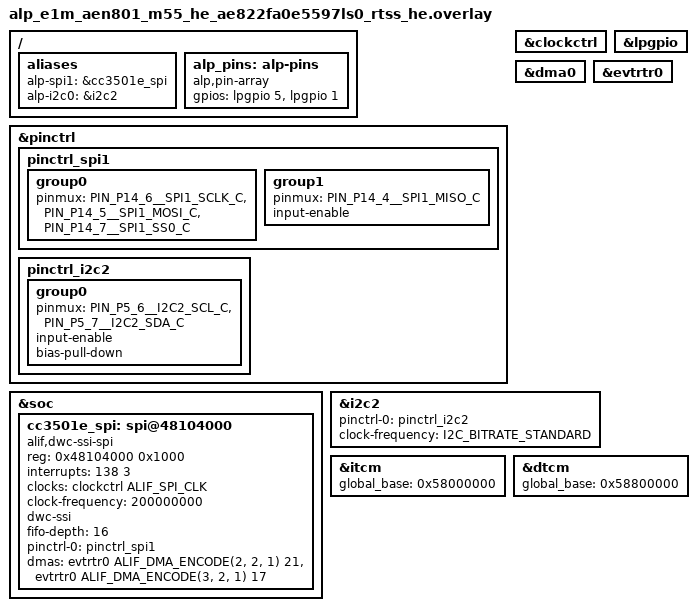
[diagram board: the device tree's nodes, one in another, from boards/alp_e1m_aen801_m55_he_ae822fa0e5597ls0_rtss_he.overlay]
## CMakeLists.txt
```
# SPDX-License-Identifier: Apache-2.0

cmake_minimum_required(VERSION 3.20)

find_package(Zephyr REQUIRED HINTS $ENV{ZEPHYR_BASE})
project(aen_cc3501e_companion_tour LANGUAGES C)

target_sources(app PRIVATE src/main.c)
# Reusable SoM bring-up helper (cc3501e_bridge_bringup): the one-call CC3501E
# bridge init the example + applications use. Copyable template -- see
# cc3501e_bridge.h. (Same helper as aen-cc3501e-bringup; examples are meant to
# be self-contained, copyable starting points.)
target_sources(app PRIVATE src/cc3501e_bridge.c)
# E1M-AEN GPIO-proxy route table: strong override of the WEAK
# cc3501e_gpio_routes[] in src/backends/gpio/cc3501e_proxy_routes_weak.c
# (E1M IO pin_id -> raw CC3501E GPIO). Auto-generated by
# scripts/gen_cc3501e_gpio_routes.py -- do not edit by hand, regenerate.
# Built unconditionally; only consulted when CONFIG_ALP_SDK_GPIO_CC3501E_PROXY is on.
target_sources(app PRIVATE src/cc3501e_gpio_routes.c)
```

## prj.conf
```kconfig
# SPDX-License-Identifier: Apache-2.0
#
# CONFIG_SPI / CONFIG_GPIO are pulled in from board.yaml's `peripherals:`
# block (via the generated alp.conf); this file carries only the console.
CONFIG_PRINTK=y
CONFIG_LOG=y

# The tour uses busy/sleep waits + a few driver scratch buffers + a socket
# receive buffer; a generous main-thread stack keeps them comfortable.
CONFIG_MAIN_STACK_SIZE=4096

# Link the app at the HE MRAM app partition (0x80010000) so its vector table
# matches the ATOC load address (app-zephyr-he.json mramAddress=0x80010000).
# FLASH_BASE is the full MRAM (0x80000000); without this 0x10000 offset the
# image links at 0x80000000 and the SES boots it 64 KB low -> fault/no-boot.
CONFIG_FLASH_LOAD_OFFSET=0x10000

# Route the proxied E1M IOs (cc3501e_gpio_routes[] in src/cc3501e_gpio_routes.c)
# through the CC3501E bridge: alp_gpio_open(ALP_E1M_GPIO_IOxx) for a mapped IO
# goes over the inter-chip link; the Alif's own pins delegate to the platform
# GPIO driver.  The final tour step reads a proxied IO through this path.
CONFIG_ALP_SDK_GPIO_CC3501E_PROXY=y
```

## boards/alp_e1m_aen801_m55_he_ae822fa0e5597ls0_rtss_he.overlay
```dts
/*
 * Copyright (c) 2026 Alp Lab AB
 * SPDX-License-Identifier: Apache-2.0
 *
 * Inter-chip wiring for the CC3501E bring-up on the E1M-AEN801 (Alif
 * Ensemble E8, M55-HE).  Declares the SoM-internal Alif<->CC3501E link:
 * the SPI1 master bus + the two host-driven control nets, all from
 * metadata/e1m_modules/aen/inter-chip.tsv:
 *
 *   SPI1.SCK  P14_6   SPI1.MOSI P14_5   SPI1.MISO P14_4   (-> CC3501E GPIO_27/28/29)
 *   WIFI_EN   P15_5 (lpgpio 5)          E_WIFI.NRST P15_1_FLEX (lpgpio 1)
 *
 * "P15" is the Alif low-power GPIO island (lpgpio @ 0x42002000); the
 * _FLEX pads are its pins.  P14 is a main-domain port used here purely as
 * the SPI1 function via pinctrl, so no gpio14 controller node is needed.
 *
 * BENCH-UNVERIFIED.  Like the rest of the alp-sdk Alif peripheral layer
 * (zephyr/dts/alif/ensemble_e8_peripherals.dtsi), the addresses/IRQs are
 * transcribed from the Apache-2.0 alifsemi/zephyr_alif fork + the AE822
 * TRM and have NOT been validated on silicon.  The SPI1 pinctrl macros are
 * RESOLVED against zephyr/dt-bindings/pinctrl/alif-ensemble-pinctrl.h
 * (SPI1 on P14_4/5/6 = alt-2, the `_C` suffix) and the LP-GPIO mux is the
 * reset default (alt-0 = LPGPIO); the one remaining genuine unknown is the
 * SPI1 IRQ number (upstream Zephyr declares no SPI node, so it is not in
 * the build tree) -- confirm it against the AE822 TRM before relying on
 * the interrupt-driven path on silicon.
 *
 * Also enables i2c2 (P5_6 SCL_C / P5_7 SDA_C) + the `alp-i2c0` alias -- the
 * on-module EEPROM manifest bus alp_hw_info_read() opens as bus_id 0.
 * Without it the manifest read structurally cannot succeed and the banner
 * falls back to the raw board target instead of the SoM identity; see #1870.
 * Same pinctrl (input-enable + bias-pull-down) as
 * examples/peripheral-io/alp-console's bench-validated overlay -- do NOT
 * "correct" the pull direction.
 */

#include <zephyr/dt-bindings/pinctrl/alif-ensemble-pinctrl.h>
#include <zephyr/dt-bindings/gpio/gpio.h>
#include <zephyr/dt-bindings/dma/alif_dma_event_router.h>
#include <zephyr/dt-bindings/i2c/i2c.h>

&pinctrl {
	/*
	 * SPI1 master on P14_6 (SCK) / P14_5 (MOSI) / P14_4 (MISO).
	 *
	 * RESOLVED against alif-ensemble-pinctrl.h: the SPI1 functions on these
	 * three pads are alt-2, named with the `_C` suffix
	 * (PIN_P14_6__SPI1_SCLK_C = ALIF_PINMUX(14, 6, 2), etc.).  input-enable
	 * on MISO so the pad can sense the slave's drive (the same read-enable
	 * requirement the I2C pads need on this SoC).
	 */
	pinctrl_spi1: pinctrl_spi1 {
		group0 {
			/* Hardware SS0 chip-select (P14_7 = SPI1_SS0_C) -- dwc-ssi master
			 * drives SS0 per transfer to frame the CC3501E slave. */
			pinmux = <PIN_P14_6__SPI1_SCLK_C>, <PIN_P14_5__SPI1_MOSI_C>,
				 <PIN_P14_7__SPI1_SS0_C>;
		};
		group1 {
			pinmux = <PIN_P14_4__SPI1_MISO_C>;
			input-enable;
		};
	};

	/* I2C2 master (EEPROM manifest bus): SCL P5_6 / SDA P5_7 (_C).  Same
	 * pad config as alp-console's bench-validated overlay -- input-enable
	 * for ACK-detect, bias-pull-down (the pad DSC value Alif's reference
	 * uses; the bus is pulled up on the carrier via R95/R96). */
	pinctrl_i2c2: pinctrl_i2c2 {
		group0 {
			pinmux = <PIN_P5_6__I2C2_SCL_C>, <PIN_P5_7__I2C2_SDA_C>;
			input-enable;
			bias-pull-down;
		};
	};
};

/*
 * DWC_ssi SPI1 (AHB) -- the on-SoM CC3501E inter-chip link.  Deliberately
 * NOT in ensemble_e8_peripherals.dtsi (that dtsi declares only the
 * customer-facing edge SPI0); this is the SoM-internal Wi-Fi link, so it
 * lives in the consuming app's overlay.  Same driver + flags as spi0
 * (compatible "alif,dwc-ssi-spi", dwc-ssi layout, fifo-depth 16,
 * frequency-only ALIF_SPI_CLK).
 *
 * reg 0x48104000 = SPI1 base (spi0 is 0x48103000, +0x1000/instance).
 * BENCH-TBD: interrupts = <138 3> follows the consecutive pattern from
 * spi0's IRQ 137 -- confirm SPI1_IRQ against the fork's e1.dtsi / TRM.
 *
 * No cs-gpios: P14_7 is muxed as SPI1_SS0_C above and the dwc-ssi peripheral
 * drives hardware SS0 per transfer.  The host opens ALP_SPI_NO_CS so no GPIO CS
 * is installed, allowing the SPI driver to use its hardware slave-select path.
 */
&clockctrl {
	status = "okay";
};

&soc {
	cc3501e_spi: spi@48104000 {
		compatible = "alif,dwc-ssi-spi";
		#address-cells = <1>;
		#size-cells = <0>;
		reg = <0x48104000 0x1000>;
		interrupts = <138 3>;          /* BENCH-TBD: confirm SPI1 IRQ */
		clocks = <&clockctrl ALIF_SPI_CLK>;
		/*
		 * ROOT-CAUSE FIX 2026-06-16: spi_dw_alif's configure takes the
		 * clock-control path when no clock-frequency is set, and that path
		 * fails (-EINVAL) for the gateless dummy ALIF_SPI_CLK -> every
		 * transceive returned ALP_ERR_INVAL with zero SCLK (witness fail_step=1,
		 * zerr=-EINVAL). Providing the SSI input clock here makes the driver
		 * use it directly and skip the failing clock-control path. The SSI
		 * functional clock is 200 MHz (E8 HWRM); BAUDR = clk/freq_hz.
		 */
		clock-frequency = <200000000>; /* real SSI functional clock (was mis-set 400M; proven via BAUDR scaling) */
		dwc-ssi;
		fifo-depth = <16>;
		pinctrl-0 = <&pinctrl_spi1>;
		pinctrl-names = "default";
		status = "okay";
	};
};

/*
 * Enable the LP GPIO island so WIFI_EN (P15_5) and E_WIFI.NRST
 * (P15_1_FLEX) are drivable as outputs.  gpio_dw needs no clocks/pinctrl
 * on the controller, and the pad->GPIO mux needs no pinctrl group either:
 * RESOLVED against alif-ensemble-pinctrl.h -- P15_1/P15_5 function 0 (the
 * reset default) IS LPGPIO (PIN_P15_x__LPGPIO = ALIF_PINMUX(15, x, 0)).
 */
&lpgpio {
	status = "okay";
};

/* P2_6 (E1M AH7 / I2S1_SCLK) is NOT the CC3501E READY net on the R2 module this
 * bridge targets -- it is E1M pad AH7 / I2S1_SCLK, which the E1M EVK carrier
 * repurposes as the Arduino header's CK_RST (metadata/boards/e1m-evk.yaml);
 * the real READY net lands on E1M pad G3 / IO16 instead
 * (metadata/e1m_modules/aen/from-cc3501e.tsv). This app therefore does not
 * enable &gpio2 or claim P2_6 as READY -- see src/cc3501e_bridge.c and
 * chips/cc3501e/cc3501e_core.c's cc3501e_reply_gate() comment. A board (or a
 * hand-reworked r1 unit) that genuinely wires GPIO17 to P2_6 can opt back
 * in: enable &gpio2, add a pinctrl group that enables P2_6's INPUT BUFFER --
 * reset-default mux already IS GPIO, but GPIO function alone does not enable
 * the input path; skip that group and cc3501e_reply_gate()'s read comes back
 * a constant 0 forever, indistinguishable from a stuck-LOW pad -- add an
 * alp_pins entry for it, and set fw->ready_pin in cc3501e_bridge_bringup(). */

/*
 * Host-side peripheral DMA for continuous SPI streams over the CC3501E bridge.
 * SPI1 is a MAIN-domain peripheral, so per the AE822 DFP soc_dma_map (SPI1_DMA=0,
 * group 2, TX req 21 / RX req 17) it routes through the SYSTOP DMA0 via its event
 * router evtrtr0 (4 groups -> group 2 valid) -- NOT the M55-HE-local DMA2/evtrtr2
 * (1 group, for LP peripherals; wiring SPI1 there leaves the channel Waiting-For-
 * Peripheral forever -- SPI1's request line isn't on the HE router).  DMA0's clock
 * is SYSTOP (already on -- the app drives SPI1/GPIO in the same region); its
 * PL330 boot-manager security latch (CLKCTRL_PER_MST) is in dma_alif_boot_latch.c.
 * The fork PL330 driver statically allocates the per-channel ucode + remaps it via
 * local_to_global(), so no external `microcode` prop is needed.
 *
 * dma0 + evtrtr0 are now declared in ensemble_e8_peripherals.dtsi (disabled
 * by default, alp-sdk issue #1815); this overlay only enables them.
 */
&dma0 {
	status = "okay";
};

&evtrtr0 {
	status = "okay";
};

/*
 * Route the bridge SPI1 through evtrtr0 to DMA0.  Cell encoding
 * (ALIF_DMA_ENCODE(channel, dma_group, handshake), periph_req):
 *   TX = PL330 ch2, evtrtr group 2, handshake on, SPI1 TX periph req 21
 *   RX = PL330 ch3, evtrtr group 2, handshake on, SPI1 RX periph req 17
 * (AE822 DFP soc_dma_map.h: SPI1 group 2, TX 21 / RX 17.)
 */
&cc3501e_spi {
	dmas = <&evtrtr0 ALIF_DMA_ENCODE(2, 2, 1) 21>,
	       <&evtrtr0 ALIF_DMA_ENCODE(3, 2, 1) 17>;
	dma-names = "txdma", "rxdma";
};

&i2c2 {
	status = "okay";
	pinctrl-0 = <&pinctrl_i2c2>;
	pinctrl-names = "default";
	clock-frequency = <I2C_BITRATE_STANDARD>;   /* 100 kHz */
};

/ {
	aliases {
		/* bus_id 1 in alp_spi_open() -> this controller. */
		alp-spi1 = &cc3501e_spi;
		alp-i2c0 = &i2c2;   /* bus 0 for alp_hw_info_read() -> EEPROM manifest */
	};

	/*
	 * Compact 2-entry control array for the SoM-internal CC3501E control
	 * nets, in the order the app's CC3501E_PIN_* indices expect.  These are
	 * NOT E1M edge pads, so this bring-up app intentionally does NOT use the
	 * 52-slot positional E1M map; a production board file appends such
	 * SoM-internal control nets after the E1M pad slots.  No READY entry
	 * here -- see the P2_6 comment above &gpio2's removal further up.
	 */
	alp_pins: alp-pins {
		compatible = "alp,pin-array";
		gpios = <&lpgpio 5 GPIO_ACTIVE_HIGH>, /* [0] WIFI_EN     (P15_5)      */
			<&lpgpio 1 GPIO_ACTIVE_HIGH>; /* [1] E_WIFI.NRST (P15_1_FLEX) */
	};
};

/*
 * Global-bus aliases of the M55-HE TCMs, needed by hal_alif soc_memory_map.h
 * local_to_global() -- the PL330 (AXI master) reaches TCM-resident buffers only
 * via these global windows.  Values from the AE822 M55-HE map (sdk-alif fork
 * ensemble_rtss_he.dtsi): ITCM 0x0->0x58000000, DTCM 0x20000000->0x58800000.
 * (DMA stream buffers still belong in SRAM0 0x02000000, which is already global
 * -> local_to_global() returns it unchanged.)
 */
&itcm {
	global_base = <0x58000000>;
};
&dtcm {
	global_base = <0x58800000>;
};
```

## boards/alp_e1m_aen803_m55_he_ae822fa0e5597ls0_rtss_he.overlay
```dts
/*
 * Copyright (c) 2026 Alp Lab AB
 * SPDX-License-Identifier: Apache-2.0
 *
 * Inter-chip wiring for the CC3501E bring-up on the E1M-AEN803 (Alif
 * Ensemble E8, M55-HE).  Declares the SoM-internal Alif<->CC3501E link:
 * the SPI1 master bus + the two host-driven control nets, all from
 * metadata/e1m_modules/aen/inter-chip.tsv:
 *
 *   SPI1.SCK  P14_6   SPI1.MOSI P14_5   SPI1.MISO P14_4   (-> CC3501E GPIO_27/28/29)
 *   WIFI_EN   P15_5 (lpgpio 5)          E_WIFI.NRST P15_1_FLEX (lpgpio 1)
 *
 * "P15" is the Alif low-power GPIO island (lpgpio @ 0x42002000); the
 * _FLEX pads are its pins.  P14 is a main-domain port used here purely as
 * the SPI1 function via pinctrl, so no gpio14 controller node is needed.
 *
 * BENCH-UNVERIFIED.  Like the rest of the alp-sdk Alif peripheral layer
 * (zephyr/dts/alif/ensemble_e8_peripherals.dtsi), the addresses/IRQs are
 * transcribed from the Apache-2.0 alifsemi/zephyr_alif fork + the AE822
 * TRM and have NOT been validated on silicon.  The SPI1 pinctrl macros are
 * RESOLVED against zephyr/dt-bindings/pinctrl/alif-ensemble-pinctrl.h
 * (SPI1 on P14_4/5/6 = alt-2, the `_C` suffix) and the LP-GPIO mux is the
 * reset default (alt-0 = LPGPIO); the one remaining genuine unknown is the
 * SPI1 IRQ number (upstream Zephyr declares no SPI node, so it is not in
 * the build tree) -- confirm it against the AE822 TRM before relying on
 * the interrupt-driven path on silicon.
 *
 * Also enables i2c2 (P5_6 SCL_C / P5_7 SDA_C) + the `alp-i2c0` alias -- the
 * on-module EEPROM manifest bus alp_hw_info_read() opens as bus_id 0.
 * Without it the manifest read structurally cannot succeed and the banner
 * falls back to the raw board target instead of the SoM identity; see #1870.
 * Same pinctrl (input-enable + bias-pull-down) as
 * examples/peripheral-io/alp-console's bench-validated overlay -- do NOT
 * "correct" the pull direction.
 */

#include <zephyr/dt-bindings/pinctrl/alif-ensemble-pinctrl.h>
#include <zephyr/dt-bindings/gpio/gpio.h>
#include <zephyr/dt-bindings/dma/alif_dma_event_router.h>
#include <zephyr/dt-bindings/i2c/i2c.h>

&pinctrl {
	/*
	 * SPI1 master on P14_6 (SCK) / P14_5 (MOSI) / P14_4 (MISO).
	 *
	 * RESOLVED against alif-ensemble-pinctrl.h: the SPI1 functions on these
	 * three pads are alt-2, named with the `_C` suffix
	 * (PIN_P14_6__SPI1_SCLK_C = ALIF_PINMUX(14, 6, 2), etc.).  input-enable
	 * on MISO so the pad can sense the slave's drive (the same read-enable
	 * requirement the I2C pads need on this SoC).
	 */
	pinctrl_spi1: pinctrl_spi1 {
		group0 {
			/* Hardware SS0 chip-select (P14_7 = SPI1_SS0_C) -- dwc-ssi master
			 * drives SS0 per transfer to frame the CC3501E slave. */
			pinmux = <PIN_P14_6__SPI1_SCLK_C>, <PIN_P14_5__SPI1_MOSI_C>,
				 <PIN_P14_7__SPI1_SS0_C>;
		};
		group1 {
			pinmux = <PIN_P14_4__SPI1_MISO_C>;
			input-enable;
		};
	};

	/* I2C2 master (EEPROM manifest bus): SCL P5_6 / SDA P5_7 (_C).  Same
	 * pad config as alp-console's bench-validated overlay -- input-enable
	 * for ACK-detect, bias-pull-down (the pad DSC value Alif's reference
	 * uses; the bus is pulled up on the carrier via R95/R96). */
	pinctrl_i2c2: pinctrl_i2c2 {
		group0 {
			pinmux = <PIN_P5_6__I2C2_SCL_C>, <PIN_P5_7__I2C2_SDA_C>;
			input-enable;
			bias-pull-down;
		};
	};
};

/*
 * DWC_ssi SPI1 (AHB) -- the on-SoM CC3501E inter-chip link.  Deliberately
 * NOT in ensemble_e8_peripherals.dtsi (that dtsi declares only the
 * customer-facing edge SPI0); this is the SoM-internal Wi-Fi link, so it
 * lives in the consuming app's overlay.  Same driver + flags as spi0
 * (compatible "alif,dwc-ssi-spi", dwc-ssi layout, fifo-depth 16,
 * frequency-only ALIF_SPI_CLK).
 *
 * reg 0x48104000 = SPI1 base (spi0 is 0x48103000, +0x1000/instance).
 * BENCH-TBD: interrupts = <138 3> follows the consecutive pattern from
 * spi0's IRQ 137 -- confirm SPI1_IRQ against the fork's e1.dtsi / TRM.
 *
 * No cs-gpios: P14_7 is muxed as SPI1_SS0_C above and the dwc-ssi peripheral
 * drives hardware SS0 per transfer.  The host opens ALP_SPI_NO_CS so no GPIO CS
 * is installed, allowing the SPI driver to use its hardware slave-select path.
 */
&clockctrl {
	status = "okay";
};

&soc {
	cc3501e_spi: spi@48104000 {
		compatible = "alif,dwc-ssi-spi";
		#address-cells = <1>;
		#size-cells = <0>;
		reg = <0x48104000 0x1000>;
		interrupts = <138 3>;          /* BENCH-TBD: confirm SPI1 IRQ */
		clocks = <&clockctrl ALIF_SPI_CLK>;
		/*
		 * ROOT-CAUSE FIX 2026-06-16: spi_dw_alif's configure takes the
		 * clock-control path when no clock-frequency is set, and that path
		 * fails (-EINVAL) for the gateless dummy ALIF_SPI_CLK -> every
		 * transceive returned ALP_ERR_INVAL with zero SCLK (witness fail_step=1,
		 * zerr=-EINVAL). Providing the SSI input clock here makes the driver
		 * use it directly and skip the failing clock-control path. The SSI
		 * functional clock is 200 MHz (E8 HWRM); BAUDR = clk/freq_hz.
		 */
		clock-frequency = <200000000>; /* real SSI functional clock (was mis-set 400M; proven via BAUDR scaling) */
		dwc-ssi;
		fifo-depth = <16>;
		pinctrl-0 = <&pinctrl_spi1>;
		pinctrl-names = "default";
		status = "okay";
	};
};

/*
 * Enable the LP GPIO island so WIFI_EN (P15_5) and E_WIFI.NRST
 * (P15_1_FLEX) are drivable as outputs.  gpio_dw needs no clocks/pinctrl
 * on the controller, and the pad->GPIO mux needs no pinctrl group either:
 * RESOLVED against alif-ensemble-pinctrl.h -- P15_1/P15_5 function 0 (the
 * reset default) IS LPGPIO (PIN_P15_x__LPGPIO = ALIF_PINMUX(15, x, 0)).
 */
&lpgpio {
	status = "okay";
};

/* P2_6 (E1M AH7 / I2S1_SCLK) is NOT the CC3501E READY net on the R2 module this
 * bridge targets -- it is E1M pad AH7 / I2S1_SCLK, which the E1M EVK carrier
 * repurposes as the Arduino header's CK_RST (metadata/boards/e1m-evk.yaml);
 * the real READY net lands on E1M pad G3 / IO16 instead
 * (metadata/e1m_modules/aen/from-cc3501e.tsv). This app therefore does not
 * enable &gpio2 or claim P2_6 as READY -- see src/cc3501e_bridge.c and
 * chips/cc3501e/cc3501e_core.c's cc3501e_reply_gate() comment. A board (or a
 * hand-reworked r1 unit) that genuinely wires GPIO17 to P2_6 can opt back
 * in: enable &gpio2, add a pinctrl group that enables P2_6's INPUT BUFFER --
 * reset-default mux already IS GPIO, but GPIO function alone does not enable
 * the input path; skip that group and cc3501e_reply_gate()'s read comes back
 * a constant 0 forever, indistinguishable from a stuck-LOW pad -- add an
 * alp_pins entry for it, and set fw->ready_pin in cc3501e_bridge_bringup(). */

/*
 * Host-side peripheral DMA for continuous SPI streams over the CC3501E bridge.
 * SPI1 is a MAIN-domain peripheral, so per the AE822 DFP soc_dma_map (SPI1_DMA=0,
 * group 2, TX req 21 / RX req 17) it routes through the SYSTOP DMA0 via its event
 * router evtrtr0 (4 groups -> group 2 valid) -- NOT the M55-HE-local DMA2/evtrtr2
 * (1 group, for LP peripherals; wiring SPI1 there leaves the channel Waiting-For-
 * Peripheral forever -- SPI1's request line isn't on the HE router).  DMA0's clock
 * is SYSTOP (already on -- the app drives SPI1/GPIO in the same region); its
 * PL330 boot-manager security latch (CLKCTRL_PER_MST) is in dma_alif_boot_latch.c.
 * The fork PL330 driver statically allocates the per-channel ucode + remaps it via
 * local_to_global(), so no external `microcode` prop is needed.
 *
 * dma0 + evtrtr0 are now declared in ensemble_e8_peripherals.dtsi (disabled
 * by default, alp-sdk issue #1815); this overlay only enables them.
 */
&dma0 {
	status = "okay";
};

&evtrtr0 {
	status = "okay";
};

/*
 * Route the bridge SPI1 through evtrtr0 to DMA0.  Cell encoding
 * (ALIF_DMA_ENCODE(channel, dma_group, handshake), periph_req):
 *   TX = PL330 ch2, evtrtr group 2, handshake on, SPI1 TX periph req 21
 *   RX = PL330 ch3, evtrtr group 2, handshake on, SPI1 RX periph req 17
 * (AE822 DFP soc_dma_map.h: SPI1 group 2, TX 21 / RX 17.)
 */
&cc3501e_spi {
	dmas = <&evtrtr0 ALIF_DMA_ENCODE(2, 2, 1) 21>,
	       <&evtrtr0 ALIF_DMA_ENCODE(3, 2, 1) 17>;
	dma-names = "txdma", "rxdma";
};

&i2c2 {
	status = "okay";
	pinctrl-0 = <&pinctrl_i2c2>;
	pinctrl-names = "default";
	clock-frequency = <I2C_BITRATE_STANDARD>;   /* 100 kHz */
};

/ {
	aliases {
		/* bus_id 1 in alp_spi_open() -> this controller. */
		alp-spi1 = &cc3501e_spi;
		alp-i2c0 = &i2c2;   /* bus 0 for alp_hw_info_read() -> EEPROM manifest */
	};

	/*
	 * Compact 2-entry control array for the SoM-internal CC3501E control
	 * nets, in the order the app's CC3501E_PIN_* indices expect.  These are
	 * NOT E1M edge pads, so this bring-up app intentionally does NOT use the
	 * 52-slot positional E1M map; a production board file appends such
	 * SoM-internal control nets after the E1M pad slots.  No READY entry
	 * here -- see the P2_6 comment above &gpio2's removal further up.
	 */
	alp_pins: alp-pins {
		compatible = "alp,pin-array";
		gpios = <&lpgpio 5 GPIO_ACTIVE_HIGH>, /* [0] WIFI_EN     (P15_5)      */
			<&lpgpio 1 GPIO_ACTIVE_HIGH>; /* [1] E_WIFI.NRST (P15_1_FLEX) */
	};
};

/*
 * Global-bus aliases of the M55-HE TCMs, needed by hal_alif soc_memory_map.h
 * local_to_global() -- the PL330 (AXI master) reaches TCM-resident buffers only
 * via these global windows.  Values from the AE822 M55-HE map (sdk-alif fork
 * ensemble_rtss_he.dtsi): ITCM 0x0->0x58000000, DTCM 0x20000000->0x58800000.
 * (DMA stream buffers still belong in SRAM0 0x02000000, which is already global
 * -> local_to_global() returns it unchanged.)
 */
&itcm {
	global_base = <0x58000000>;
};
&dtcm {
	global_base = <0x58800000>;
};
```

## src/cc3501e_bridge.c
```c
/*
 * SPDX-License-Identifier: Apache-2.0
 * Copyright 2026 Alp Lab AB
 *
 * E1M-AEN SoM CC3501E bridge bring-up helper -- see cc3501e_bridge.h.
 */

#include "cc3501e_bridge.h"

#if defined(CONFIG_BOARD_ALP_E1M_AEN801_M55_HE)
#include <zephyr/arch/cpu.h>
#include <zephyr/sys/sys_io.h>
/*
 * AEN LP-pad mux (Alif Ensemble E8, M55-HE).  WIFI_EN (P15_5) and nRESET (P15_1)
 * are on the Alif LP-GPIO island, bound by the generic snps,designware-gpio driver
 * which does NOT apply Alif pinctrl -- so the LP pads stay un-muxed and their output
 * drivers OFF (confirmed on silicon: WIFI_EN never powers the CC3501E until these
 * regs are set).  0x23 = the Alif GPIO-output pad config (driver + read-enable +
 * drive strength).  TODO: drop this raw poke once the Alif GPIO backend muxes the LP
 * island via pinctrl.
 */
#define ALIF_LPGPIO_PADCTRL_BASE 0x42007000u
#define ALIF_PAD_GPIO_OUTPUT     0x23u
static void aen_lp_pads_enable_output(void)
{
	sys_write32(ALIF_PAD_GPIO_OUTPUT, ALIF_LPGPIO_PADCTRL_BASE + 5u * 4u); /* P15_5 WIFI_EN */
	sys_write32(ALIF_PAD_GPIO_OUTPUT, ALIF_LPGPIO_PADCTRL_BASE + 1u * 4u); /* P15_1 nRESET  */
}
#else
static inline void aen_lp_pads_enable_output(void)
{
}
#endif

alp_status_t cc3501e_bridge_bringup(cc3501e_t *fw)
{
	if (fw == NULL) {
		return ALP_ERR_INVAL;
	}

	/* 1. Control pins: WIFI_EN (supply gate) + nRESET.  These are Alif LP-GPIO
	 *    pads, not E1M edge pads -- the SoM owns them. */
	alp_gpio_t *wifi_en = alp_gpio_open(CC3501E_BRIDGE_PIN_WIFI_EN);
	alp_gpio_t *nrst    = alp_gpio_open(CC3501E_BRIDGE_PIN_NRST);
	if (wifi_en == NULL || nrst == NULL) {
		if (wifi_en != NULL) {
			alp_gpio_close(wifi_en);
		}
		if (nrst != NULL) {
			alp_gpio_close(nrst);
		}
		return ALP_ERR_NOT_PRESENT_ON_THIS_SOC;
	}
	aen_lp_pads_enable_output();
	(void)alp_gpio_configure(wifi_en, ALP_GPIO_OUTPUT, ALP_GPIO_PULL_NONE);
	(void)alp_gpio_configure(nrst, ALP_GPIO_OUTPUT, ALP_GPIO_PULL_NONE);

	/* 2. Inter-chip SPI (Alif = master).  No chip-select this HW rev -- the link is
	 *    fixed-count lockstep (ALP_SPI_NO_CS); mode 0 matches the CC3501E vendor
	 *    image frameFormat. */
	alp_spi_t *spi = alp_spi_open(&(alp_spi_config_t){
	    .bus_id        = CC3501E_BRIDGE_SPI_BUS_ID,
	    .freq_hz       = CC3501E_BRIDGE_SPI_FREQ_HZ,
	    .mode          = ALP_SPI_MODE_0,
	    .bits_per_word = 8u,
	    .cs_pin_id     = ALP_SPI_NO_CS,
	});
	if (spi == NULL) {
		alp_gpio_close(wifi_en);
		alp_gpio_close(nrst);
		return ALP_ERR_NOT_PRESENT_ON_THIS_SOC;
	}

#if CC3501E_BRIDGE_RX_SAMPLE_DLY > 0
	/* Raise the SCLK past 1 MHz: the DW SSI RX_SAMPLE_DLY register (0xf0) delays
	 * the MISO capture point by N ssi_clk cycles to cover the on-SoM trace + crossed
	 * data round-trip.  Zephyr spi_dw never writes it (leaves 0), so without this
	 * >1 MHz mis-samples MISO (cold reqhdr_rx=0xFFFFFFFF).  Written with SSI disabled
	 * (SSIENR=0); persists across the driver's per-transfer configure.  Value is
	 * silicon-tuned -- sweep CC3501E_BRIDGE_RX_SAMPLE_DLY at the target SCLK. */
	{
		volatile uint32_t *ssienr =
		    (volatile uint32_t *)(uintptr_t)(CC3501E_BRIDGE_SPI1_BASE + 0x08u);
		volatile uint32_t *rsd = (volatile uint32_t *)(uintptr_t)(CC3501E_BRIDGE_SPI1_BASE + 0xf0u);
		uint32_t           en  = *ssienr;
		*ssienr                = 0u;
		*rsd                   = (uint32_t)CC3501E_BRIDGE_RX_SAMPLE_DLY;
		*ssienr                = en;
	}
#endif

	/* 3. Bind the bus + control pins; attach the GPIO proxy (proxied E1M IOs then
	 *    route over the bridge); run the power + reset sequence (TI SWRU626 + the
	 *    Puya cold-boot hard-reset workaround).  Leaves WIFI_EN HIGH. */
	(void)cc3501e_init(fw, spi);
	fw->enable_pin = wifi_en;
	fw->reset_pin  = nrst;
	/* Optional host-IRQ/READY line (r2 SS0+IRQ bridge): CC35 GPIO17 -> Alif P2_6.
	 * Open + configure as input; if the board doesn't wire it (alp_pins[2] absent),
	 * alp_gpio_open returns NULL and the driver keeps the fixed-gap fallback. */
	alp_gpio_t *ready = alp_gpio_open(CC3501E_BRIDGE_PIN_READY);
	if (ready != NULL) {
		(void)alp_gpio_configure(ready, ALP_GPIO_INPUT, ALP_GPIO_PULL_NONE);
		fw->ready_pin = ready;
	}
#ifdef CONFIG_ALP_SDK_GPIO_CC3501E_PROXY
	(void)alp_gpio_cc3501e_attach(fw);
#endif
	return cc3501e_reset(fw);
}
```

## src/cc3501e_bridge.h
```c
/*
 * SPDX-License-Identifier: Apache-2.0
 * Copyright 2026 Alp Lab AB
 *
 * One-call bring-up of the E1M-AEN SoM's CC3501E Wi-Fi 6 / BLE coprocessor over the
 * inter-chip SPI bridge -- the SoM bring-up TEMPLATE for applications.
 *
 * The CC3501E is part of the SoM (module U4 = BDE-BW35N): the application does NOT
 * touch the raw SPI bus or the WIFI_EN / nRESET control pins.  It calls
 * cc3501e_bridge_bringup() once, gets a ready @ref cc3501e_t, and from there uses the
 * portable surfaces:
 *   - cc3501e_* (chips/cc3501e)            -- MAC / Wi-Fi / BLE / GPIO-proxy / OTA
 *   - alp_gpio_open(ALP_E1M_GPIO_IOxx)         -- proxied E1M IOs (when the proxy is built)
 *
 * To reuse in your own AEN application: copy this pair (cc3501e_bridge.{c,h}) into your
 * app, or call cc3501e_bridge_bringup() directly.  The bus / pins / clock are the
 * E1M-AEN SoM defaults below; a board variant overrides only those macros -- the SoM
 * stays swappable without touching application code.
 */

#ifndef CC3501E_BRIDGE_H
#define CC3501E_BRIDGE_H

#include <alp/peripheral.h>    /* alp_status_t */
#include <alp/chips/cc3501e.h> /* cc3501e_t */

/* ---- E1M-AEN SoM bridge defaults (override per board variant) ---------------- */

/* Inter-chip SPI: Alif = master, CC3501E = slave.  P14_7 is muxed as the
 * dwc-ssi hardware SS0 chip-select; ALP_SPI_NO_CS means "no software GPIO CS"
 * here, so the controller frames each protocol phase.  Mode 0 matches the
 * CC3501E vendor image frameFormat. */
#ifndef CC3501E_BRIDGE_SPI_BUS_ID
#define CC3501E_BRIDGE_SPI_BUS_ID 1u
#endif
#ifndef CC3501E_BRIDGE_SPI_FREQ_HZ
/* 25 MHz = 200 MHz SSI functional clock / 8.
 *
 * The CC3501E peripheral-mode maximum is 30 MHz, NOT the 15 MHz this comment
 * claimed for most of the bring-up: datasheet SWRS343A section 6.14.2.3.3,
 * `fsclk SPI clock frequency, Peripheral Mode, MAX 30 MHz` (Controller Mode is
 * 40 MHz).  Every earlier ceiling argument here was built on the wrong number.
 *
 * 25 MHz is the fastest LEGAL step available: the DW SSI BAUDR divisor must be
 * EVEN, so from 200 MHz the neighbours are /8 = 25 MHz and /6 = 33.3 MHz, and
 * 33.3 is 11% over the part's maximum.  Reaching exactly 30 MHz would require
 * retargeting the SSI functional clock itself (AE822 HWRM section 8.3.5) --
 * ALIF_SPI_CLK is a frequency-only dummy in the dtsi with no divider control,
 * so there is no software knob for it here.
 *
 * REQUIRES an RX sample delay: at a 40 ns bit period the MISO capture does not
 * land on its own.  That delay comes from CC3501E_BRIDGE_RX_SAMPLE_DLY below --
 * NOT from the SPI node's `rx-delay` property, which the poke in
 * cc3501e_bridge.c overwrites.  The measured working span is in that constant's
 * comment.
 *
 * It does not raise throughput -- silicon-measured
 * 2026-08-24: 682 kB/s at 25 MHz vs 678 kB/s at 14.29 MHz on PIO, 704 vs 701 on
 * DMA, because wire time is only ~554 us of a ~2459 us transaction and the rest
 * is per-frame protocol cost on both ends.  It is worth taking anyway: each
 * transfer occupies the bus for ~44% less time, which is CPU and bus budget
 * handed back to everything else on the SoM.
 *
 * The 14.29 MHz predecessor was scope-confirmed at 14.20-14.26 MHz, which is
 * what validates the 200 MHz functional-clock figure the divider assumes.  A
 * board with longer traces should re-check MISO capture before adopting 25 MHz.
 *
 * SEPARATE, PRE-EXISTING DEFECT (do not blame this clock for it): a bulk read
 * intermittently desyncs partway through -- roughly 1 run in 2-3, at anywhere
 * from 61 kB to 212 kB in -- and then never recovers for the caller's whole
 * retry budget.  It reproduces at 14.29 MHz TOO, so it is not a clock artifact.
 * Signature (host-side, request-header phase of CMD_SOCK_RECV 0x23): the
 * slave's in-band idle marker reads [02 00 00 00] once and then [00 00 00 00]
 * forever instead of A5 A5 A5 A5 -- i.e. the slave is stuck mid-reply on a
 * transfer it armed earlier and never completed.  With
 * SPI_TRANSFER_RETURN_PARTIAL deliberately off, a CS deassert does not complete
 * it, and NEITHER slave self-heal fires (g_resync_count does not move -- the
 * slave is not misframing; g_arm_fail_count does not move -- the arm succeeded).
 * Clocking a full idle frame from the host to satisfy the outstanding count was
 * tried and did NOT recover it.  The fix likely belongs on the slave: a
 * stall watchdog that calls bridge_transport_spi_hw_reinit() when an armed
 * transfer has not completed for N ms. */
#define CC3501E_BRIDGE_SPI_FREQ_HZ 25000000u
#endif

/* CC3501E control pins on the Alif LP-GPIO island (NOT E1M edge pads):
 * WIFI_EN = supply gate (P15_5), nRESET = reset (P15_1_FLEX). */
#ifndef CC3501E_BRIDGE_PIN_WIFI_EN
#define CC3501E_BRIDGE_PIN_WIFI_EN 0u
#endif
#ifndef CC3501E_BRIDGE_PIN_NRST
#define CC3501E_BRIDGE_PIN_NRST 1u
#endif
/* OPTIONAL host-IRQ/READY input.  ready_pin has no fixed index or macro
 * here on purpose: on a board where the CC3501E's GPIO17 READY net is
 * actually routed to the host, set fw->ready_pin (in
 * cc3501e_bridge_bringup() below) to whatever Alif pin that board wires it
 * to.  When set, cc3501e_reply_gate() (chips/cc3501e/cc3501e_core.c) can
 * only ever ADD delay to a reply phase, never remove it, so opting in on a
 * board where the wiring is wrong costs up to 3 x 250 ms of busy-wait per
 * latch cycle before the driver's own (recoverable) stuck-LOW latch gives up
 * on it -- longer thresholds apply after each re-latch if the line flaps
 * instead of staying cleanly stuck (chips/cc3501e/cc3501e_core.c's
 * g_ready_stuck_low_threshold) -- it is always safe to try FOR LINK TIMING.
 * It is not free, though: this
 * wait runs while cc3501e_request() holds its internal transport lock, so
 * a wrong or slow ready_pin can make another caller on the same ctx see
 * ALP_ERR_BUSY after CONFIG_ALP_SDK_CC3501E_REQUEST_LOCK_TIMEOUT_MS -- see
 * <alp/chips/cc3501e/core.h>'s ready_pin doc.
 *
 * NOT Alif P2_6 on an R2 AEN EVK bench module: P2_6 there is E1M pad AH7 /
 * I2S1_SCLK (the EVK's Arduino CK_RST, metadata/boards/e1m-evk.yaml), and
 * the CC3501E GPIO17 READY net lands on E1M pad G3 / IO16 instead
 * (metadata/e1m_modules/aen/from-cc3501e.tsv).  cc3501e_bridge_bringup()
 * below leaves ready_pin NULL by default on that module -- see
 * cc3501e_reply_gate()'s own doc comment for the bench evidence. */

/* DW SSI SPI1 base (0x48104000) + RX_SAMPLE_DLY to run the bridge SCLK above
 * 1 MHz.  spi_dw_configure never writes RX_SAMPLE_DLY (0xf0), so without the
 * poke in cc3501e_bridge.c the master samples MISO at the SCLK edge, before the
 * on-SoM trace + crossed-data round-trip returns the CC35's bit, and anything
 * above 1 MHz mis-samples.  Setting it delays the capture by N ssi_clk
 * (200 MHz) cycles -- 5 ns per step.
 *
 * 4 is silicon-measured at the 25 MHz working point (40 ns bit period) on
 * E1M-AEN803 serial 2026W36-0002.  N was swept 0..10 with 0x481040F0 read back
 * each time to confirm the value took, using aen-evk-demo phase 8 as the
 * workload:
 *
 *   N = 0..7   PASS, 2-3 runs each: bring-up 0, PING on attempt 1 of 25,
 *              byte-exact MAC, scan 0, BLE 0.
 *   N = 8      FAIL, 3 runs of 3: bring-up still returns 0, but the link never
 *              answers -- PING -> -5 after all 25 attempts.
 *   N = 9      PASS, 2 runs of 2.
 *   N = 10     PASS, 3 runs of 3, but one run returned a MAC with a single bit
 *              flipped in byte 0.
 *
 * 4 is the centre of the measured-good 0..7 span: +4 steps (20 ns, half a bit
 * period) below the failure, and the low side is not a cliff at all since 0
 * itself is clean.  Do NOT read 8/9/10 as a monotone upper boundary -- 8
 * hard-fails while 9 and 10 pass, which this sweep did not explain.  Treat
 * everything above 7 as unqualified, not as graded margin.
 *
 * The "4..8 all clean cold+warm" window this comment used to claim was taken on
 * an earlier bench run at ~14.3 MHz -- a different board at roughly half the clock,
 * so it is not comparable and is not evidence for 25 MHz on this one.
 *
 * 0 does NOT mean "no delay": it compiles the poke out, leaving whatever the
 * SPI node's `rx-delay` property put there (see cc3501e_bridge.c).  Re-sweep if
 * the SoM trace lengths or the SCLK change. */
#ifndef CC3501E_BRIDGE_SPI1_BASE
#define CC3501E_BRIDGE_SPI1_BASE 0x48104000u
#endif
#ifndef CC3501E_BRIDGE_RX_SAMPLE_DLY
#define CC3501E_BRIDGE_RX_SAMPLE_DLY 4u
#endif

/**
 * @brief Bring up the SoM's CC3501E coprocessor over the inter-chip bridge.
 *
 * Opens the hardware-SS0 bridge SPI + the WIFI_EN / nRESET control pins, binds
 * them to @p fw, attaches the GPIO proxy (when CONFIG_ALP_SDK_GPIO_CC3501E_PROXY is
 * built), and runs the power + reset sequence (TI SWRU626 + the Puya cold-boot
 * hard-reset workaround).  Blocks ~900 ms for the boot budget; leaves WIFI_EN HIGH.
 *
 * @param fw  Caller-owned handle, populated on success.  Use it with cc3501e_*.
 * @return ALP_OK with @p fw ready; ALP_ERR_NOT_PRESENT_ON_THIS_SOC if the SPI bus /
 *         control pins are absent (check the board overlay); otherwise the reset
 *         sequence status.  On any failure @p fw is left un-bound (do not use it).
 */
alp_status_t cc3501e_bridge_bringup(cc3501e_t *fw);

#endif /* CC3501E_BRIDGE_H */
```

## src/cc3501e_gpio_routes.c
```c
/*
 * SPDX-License-Identifier: Apache-2.0
 * Copyright 2026 Alp Lab AB
 *
 * Auto-generated for aen-cc3501e-companion-tour by scripts/gen_cc3501e_gpio_routes.py
 * from metadata/e1m_modules/E1M-AEN801.yaml `pad_routes:` (resolved for
 * hw_rev=r2 -- see metadata/e1m_modules/aen/hw-revisions.yaml
 * `pad_route_overrides:` when board.yaml sets `som.hw_rev:`).
 * DO NOT EDIT BY HAND -- regenerate:
 *   python3 scripts/gen_cc3501e_gpio_routes.py
 *
 * Strong override of the WEAK cc3501e_gpio_routes[] /
 * cc3501e_gpio_route_count in
 * src/backends/gpio/cc3501e_proxy_routes_weak.c.  Maps the portable E1M
 * GPIO pin_id (alp_gpio_open(ALP_E1M_GPIO_IOxx)) to the RAW CC3501E GPIO
 * index the inter-chip bridge drives, so an alp_gpio_* call on a proxied
 * E1M IO is routed over the bridge while the Alif's own pins delegate to
 * the platform driver.
 *
 * Pads whose CC3501E target is bridge-reserved (the transport's own
 * SPI0 / console pads, or the bridge's own READY/host-IRQ + SPI0-CS
 * lines) are never emitted here -- the firmware's gpio_pad_reserved()
 * would refuse them at runtime, so the generator excludes them at
 * generation time instead (issue #1859).
 *
 * The revision-dependent pin guard (issue #2144) is NOT emitted here --
 * it does not depend on this board's own routes, so it lives in ONE
 * SDK-owned generated file instead of a per-app copy:
 * src/backends/gpio/cc3501e_rev_dependent_pins.c.
 */

#include <stdint.h>
#include <stddef.h>

#include <alp/chips/cc3501e.h>
#include <alp/e1m_pinout.h>

const cc3501e_gpio_route_t cc3501e_gpio_routes[] = {
	{ ALP_E1M_GPIO_IO8, 30u }, /* I2S0 74LVC157 /E, active low. CC3501E-proxied, not an Alif pin. */
	{ ALP_E1M_GPIO_IO9, 12u }, /* Reset output to the PCIe IO expander. */
	{ ALP_E1M_GPIO_IO10, 35u }, /* Drive high to enable I2C mux to the PCIe slot. */
	{ ALP_E1M_GPIO_IO11, 2u },  /* USB2 TMUXHS221 select: 0 = USB connector, 1 = M.2 E-key USB. */
	{ ALP_E1M_GPIO_IO13, 13u }, /* I2S0 74LVC157 S; 0 = TAS2563 amps, 1 = M.2 E-key I2S. */
	{ ALP_E1M_GPIO_IO15, 14u }, /* BMI323 INT1 (data-ready / motion / FIFO); CC3501E GPIO14. */
	{ ALP_E1M_GPIO_IO18, 18u }, /* M.2 E-key SDIO-path wake (active-low). */
	{ ALP_E1M_GPIO_IO19, 19u }, /* M.2 E-key UART-path wake (active-low). */
	{ ALP_E1M_GPIO_IO20, 26u }, /* SDIO 74LVC157 /E; drive low to enable mux. */
};

const size_t cc3501e_gpio_route_count =
    sizeof(cc3501e_gpio_routes) / sizeof(cc3501e_gpio_routes[0]);
```
